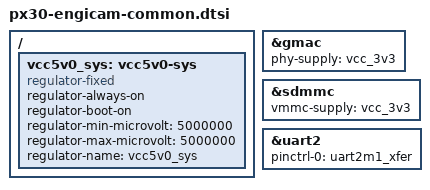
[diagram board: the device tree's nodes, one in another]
// SPDX-License-Identifier: (GPL-2.0+ OR MIT)
/*
 * Copyright (c) 2020 Engicam srl
 * Copyright (c) 2020 Amarula Solutions(India)
 */

/ {
	vcc5v0_sys: vcc5v0-sys {
		compatible = "regulator-fixed";
		regulator-always-on;
		regulator-boot-on;
		regulator-min-microvolt = <5000000>;
		regulator-max-microvolt = <5000000>;
		regulator-name = "vcc5v0_sys";	/* +5V */
	};
};

&gmac {
	phy-supply = <&vcc_3v3>;	/* +3V3_SOM */
	status = "okay";
};

&sdmmc {
	vmmc-supply = <&vcc_3v3>;	/* +3V3_SOM */
	status = "okay";
};

&uart2 {
	pinctrl-0 = <&uart2m1_xfer>;
	status = "okay";
};
